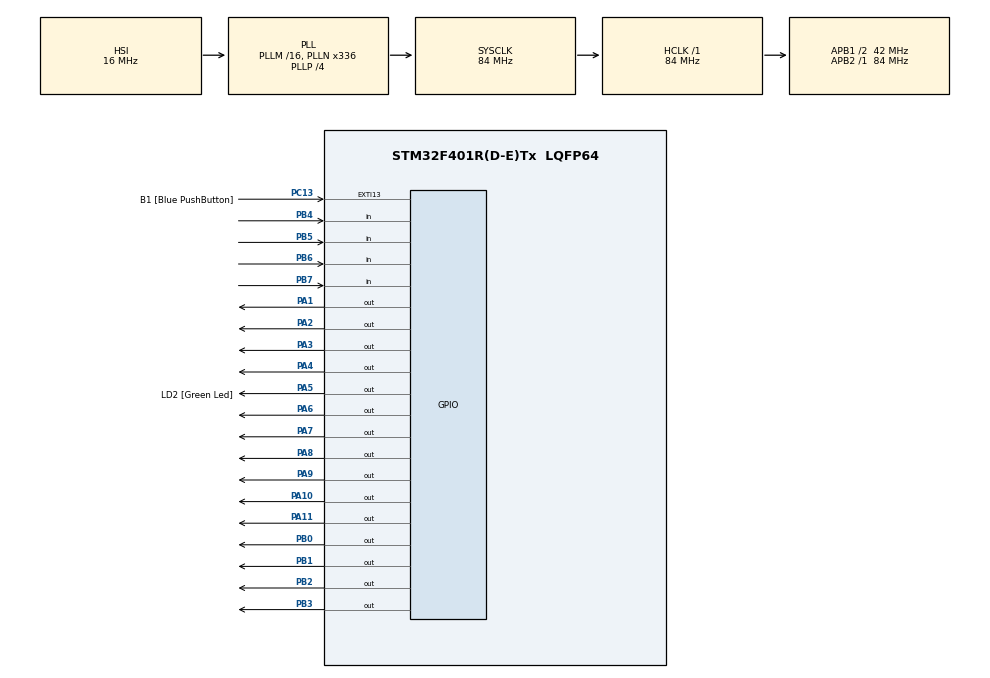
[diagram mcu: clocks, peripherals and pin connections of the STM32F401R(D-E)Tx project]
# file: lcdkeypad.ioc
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Mcu.Family=STM32F4
Mcu.Name=STM32F401R(D-E)Tx
Mcu.Package=LQFP64
NVIC.PriorityGroup=NVIC_PRIORITYGROUP_4
PA1.Signal=GPIO_Output
PA10.Signal=GPIO_Output
PA11.Signal=GPIO_Output
PA13.GPIO_Label=TMS
PA13.Signal=SYS_JTMS-SWDIO
PA14.GPIO_Label=TCK
PA14.Signal=SYS_JTCK-SWCLK
PA2.Signal=GPIO_Output
PA3.Signal=GPIO_Output
PA4.Signal=GPIO_Output
PA5.GPIO_Label=LD2 [Green Led]
PA5.GPIO_Mode=GPIO_MODE_OUTPUT_PP
PA5.GPIO_PuPd=GPIO_NOPULL
PA5.GPIO_Speed=GPIO_SPEED_FREQ_LOW
PA5.Signal=GPIO_Output
PA6.Signal=GPIO_Output
PA7.Signal=GPIO_Output
PA8.Signal=GPIO_Output
PA9.Signal=GPIO_Output
PB0.Signal=GPIO_Output
PB1.Signal=GPIO_Output
PB2.Signal=GPIO_Output
PB3.Signal=GPIO_Output
PB4.Signal=GPIO_Input
PB5.Signal=GPIO_Input
PB6.Signal=GPIO_Input
PB7.Signal=GPIO_Input
PC13-ANTI_TAMP.GPIO_Label=B1 [Blue PushButton]
PC13-ANTI_TAMP.GPIO_ModeDefaultEXTI=GPIO_MODE_IT_FALLING
PC13-ANTI_TAMP.GPIO_PuPd=GPIO_NOPULL
PC13-ANTI_TAMP.Signal=GPXTI13
PC14-OSC32_IN.Mode=LSE-External-Oscillator
PC14-OSC32_IN.Signal=RCC_OSC32_IN
PC15-OSC32_OUT.Mode=LSE-External-Oscillator
PC15-OSC32_OUT.Signal=RCC_OSC32_OUT
PH0\ -\ OSC_IN.Mode=HSE-External-Clock-Source
PH0\ -\ OSC_IN.Signal=RCC_OSC_IN
PH1\ -\ OSC_OUT.Mode=HSE-External-Clock-Source
PH1\ -\ OSC_OUT.Signal=RCC_OSC_OUT
ProjectManager.HeapSize=0x200
ProjectManager.StackSize=0x400
ProjectManager.TargetToolchain=STM32CubeIDE
RCC.48MHZClocksFreq_Value=48000000
RCC.AHBFreq_Value=84000000
RCC.APB1CLKDivider=RCC_HCLK_DIV2
RCC.APB1Freq_Value=42000000
RCC.APB1TimFreq_Value=84000000
RCC.APB2Freq_Value=84000000
RCC.APB2TimFreq_Value=84000000
RCC.CortexFreq_Value=84000000
RCC.HCLKFreq_Value=84000000
RCC.HSE_VALUE=8000000
RCC.HSI_VALUE=16000000
RCC.PLLN=336
RCC.PLLP=RCC_PLLP_DIV4
RCC.PLLQ=7
RCC.SYSCLKFreq_VALUE=84000000
RCC.SYSCLKSource=RCC_SYSCLKSOURCE_PLLCLK
RCC.VCOOutputFreq_Value=336000000
board=NUCLEO-F401RE

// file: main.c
/* USER CODE BEGIN Header */
/**
  ******************************************************************************
  * @file           : main.c
  * @brief          : Main program body
  ******************************************************************************
  * @attention
  *
  * Copyright (c) 2025 STMicroelectronics.
  * All rights reserved.
  *
  * This software is licensed under terms that can be found in the LICENSE file
  * in the root directory of this software component.
  * If no LICENSE file comes with this software, it is provided AS-IS.
  *
  ******************************************************************************
  */
/* USER CODE END Header */
#include "main.h"

void SystemClock_Config(void);
static void MX_GPIO_Init(void);
/* USER CODE BEGIN PFP */

data_pin[0] = GPIO_PIN_11;
data_pin[1] = GPIO_PIN_10;
data_pin[2] = GPIO_PIN_9;
data_pin[3] = GPIO_PIN_8;
data_pin[4] = GPIO_PIN_7;
data_pin[5] = GPIO_PIN_6;
data_pin[6] = GPIO_PIN_5;
data_pin[7] = GPIO_PIN_4;
/* USER CODE END PFP */

int main(void)
{

  /* MCU Configuration--------------------------------------------------------*/

  /* Reset of all peripherals, Initializes the Flash interface and the Systick. */
  HAL_Init();

  /* Configure the system clock */
  SystemClock_Config();

  /* Initialize all configured peripherals */
  MX_GPIO_Init();
  lcd_init();
  HAL_Delay(10);
  lcd_str((uint8_t*) "Welcome to STM32");
  lcd_cmd(0x38);
  lcd_cmd(0xC0);
  /* Infinite loop */
  while (1) {
  key_detect();
  HAL_Delay(100);
  }
  }
  void key_detect(void) {
  HAL_GPIO_WritePin(GPIOB, GPIO_PIN_3, 0);
  HAL_GPIO_WritePin(GPIOB, GPIO_PIN_2, 1);
  HAL_GPIO_WritePin(GPIOB, GPIO_PIN_1, 1);
  HAL_GPIO_WritePin(GPIOB, GPIO_PIN_0, 1);
  if (HAL_GPIO_ReadPin(GPIOB, GPIO_PIN_7) == 0) {
  //1
  lcd_cmd(0x01);
  lcd_str((uint8_t*) "You Pressed: ");
  lcd_cmd(0x38);
  lcd_cmd(0xc0);
  lcd_str((uint8_t*) "1");
  //while (HAL_GPIO_ReadPin(GPIOB, GPIO_PIN_7));
  }
  if (HAL_GPIO_ReadPin(GPIOB, GPIO_PIN_6) == 0) {
  //2
  lcd_cmd(0x01);
  lcd_str((uint8_t*) "You Pressed: ");
  lcd_cmd(0x38);
  lcd_cmd(0xc0);
  lcd_str((uint8_t*) "2");
  //while (HAL_GPIO_ReadPin(GPIOB, GPIO_PIN_6));
  }
  if (HAL_GPIO_ReadPin(GPIOB, GPIO_PIN_5) == 0) {
  //2
  lcd_cmd(0x01);
  lcd_str((uint8_t*) "You Pressed: ");
  lcd_cmd(0x38);
  lcd_cmd(0xc0);
  lcd_str((uint8_t*) "3");
  //while (HAL_GPIO_ReadPin(GPIOB, GPIO_PIN_5));
  }
  if (HAL_GPIO_ReadPin(GPIOB, GPIO_PIN_4) == 0) {
  //2
  lcd_cmd(0x01);
  lcd_str((uint8_t*) "You Pressed: ");
  lcd_cmd(0x38);
  lcd_cmd(0xc0);
  lcd_str((uint8_t*) "A");
  //while (HAL_GPIO_ReadPin(GPIOB, GPIO_PIN_4));
  }
  HAL_GPIO_WritePin(GPIOB, GPIO_PIN_3, 1);
  HAL_GPIO_WritePin(GPIOB, GPIO_PIN_2, 0);
  HAL_GPIO_WritePin(GPIOB, GPIO_PIN_1, 1);
  HAL_GPIO_WritePin(GPIOB, GPIO_PIN_0, 1);
  if (HAL_GPIO_ReadPin(GPIOB, GPIO_PIN_7) == 0) {
  //1
  lcd_cmd(0x01);
  lcd_str((uint8_t*) "You Pressed: ");
  lcd_cmd(0x38);
  lcd_cmd(0xc0);
  lcd_str((uint8_t*) "4");
  //while (HAL_GPIO_ReadPin(GPIOB, GPIO_PIN_7));
  }
  if (HAL_GPIO_ReadPin(GPIOB, GPIO_PIN_6) == 0) {
  //2
  lcd_cmd(0x01);
  lcd_str((uint8_t*) "You Pressed: ");
  lcd_cmd(0x38);
  lcd_cmd(0xc0);
  lcd_str((uint8_t*) "5");
  //while (HAL_GPIO_ReadPin(GPIOB, GPIO_PIN_6));
  }
  if (HAL_GPIO_ReadPin(GPIOB, GPIO_PIN_5) == 0) {
  //2
  lcd_cmd(0x01);
  lcd_str((uint8_t*) "You Pressed: ");
  lcd_cmd(0x38);
  lcd_cmd(0xc0);
  lcd_str((uint8_t*) "6");
  //while (HAL_GPIO_ReadPin(GPIOB, GPIO_PIN_5));
  }
  if (HAL_GPIO_ReadPin(GPIOB, GPIO_PIN_4) == 0) {
  //2
  lcd_cmd(0x01);
  lcd_str((uint8_t*) "You Pressed: ");
  lcd_cmd(0x38);
  lcd_cmd(0xc0);
  lcd_str((uint8_t*) "B");
  //while (HAL_GPIO_ReadPin(GPIOB, GPIO_PIN_4));
  }
  HAL_GPIO_WritePin(GPIOB, GPIO_PIN_3, 1);
  HAL_GPIO_WritePin(GPIOB, GPIO_PIN_2, 1);
  HAL_GPIO_WritePin(GPIOB, GPIO_PIN_1, 0);
  HAL_GPIO_WritePin(GPIOB, GPIO_PIN_0, 1);
  if (HAL_GPIO_ReadPin(GPIOB, GPIO_PIN_7) == 0) {
  //1
  lcd_cmd(0x01);
  lcd_str((uint8_t*) "You Pressed: ");
  lcd_cmd(0x38);
  lcd_cmd(0xc0);
  lcd_str((uint8_t*) "7");
  //while (HAL_GPIO_ReadPin(GPIOB, GPIO_PIN_7));
  }
  if (HAL_GPIO_ReadPin(GPIOB, GPIO_PIN_6) == 0) {
  //2
  lcd_cmd(0x01);
  lcd_str((uint8_t*) "You Pressed: ");
  lcd_cmd(0x38);
  lcd_cmd(0xc0);
  lcd_str((uint8_t*) "8");
  //while (HAL_GPIO_ReadPin(GPIOB, GPIO_PIN_6));
  }
  if (HAL_GPIO_ReadPin(GPIOB, GPIO_PIN_5) == 0) {
  //2
  lcd_cmd(0x01);
  lcd_str((uint8_t*) "You Pressed: ");
  lcd_cmd(0x38);
  lcd_cmd(0xc0);
  lcd_str((uint8_t*) "9");
  //while (HAL_GPIO_ReadPin(GPIOB, GPIO_PIN_5));
  }
  if (HAL_GPIO_ReadPin(GPIOB, GPIO_PIN_4) == 0) {
  //2
  lcd_cmd(0x01);
  lcd_str((uint8_t*) "You Pressed: ");
  lcd_cmd(0x38);
  lcd_cmd(0xc0);
  lcd_str((uint8_t*) "C");
  //while (HAL_GPIO_ReadPin(GPIOB, GPIO_PIN_4));
  }
  HAL_GPIO_WritePin(GPIOB, GPIO_PIN_3, 0);
  HAL_GPIO_WritePin(GPIOB, GPIO_PIN_2, 0);
  HAL_GPIO_WritePin(GPIOB, GPIO_PIN_1, 0);
  HAL_GPIO_WritePin(GPIOB, GPIO_PIN_0, 1);
  if (HAL_GPIO_ReadPin(GPIOB, GPIO_PIN_7) == 0) {
  //1
  lcd_cmd(0x01);
  lcd_str((uint8_t*) "You Pressed: ");
  lcd_cmd(0x38);
  lcd_cmd(0xc0);
  lcd_str((uint8_t*) "*");
  //while (HAL_GPIO_ReadPin(GPIOB, GPIO_PIN_7));
  }
  if (HAL_GPIO_ReadPin(GPIOB, GPIO_PIN_6) == 0) {
  //2
  lcd_cmd(0x01);
  lcd_str((uint8_t*) "You Pressed: ");
  lcd_cmd(0x38);
  lcd_cmd(0xc0);
  lcd_str((uint8_t*) "0");
  //while (HAL_GPIO_ReadPin(GPIOB, GPIO_PIN_6));
  }
  if (HAL_GPIO_ReadPin(GPIOB, GPIO_PIN_5) == 0) {
  //2
  lcd_cmd(0x01);
  lcd_str((uint8_t*) "You Pressed: ");
  lcd_cmd(0x38);
  lcd_cmd(0xc0);
  lcd_str((uint8_t*) "#");
  //while (HAL_GPIO_ReadPin(GPIOB, GPIO_PIN_5));
  }
  if (HAL_GPIO_ReadPin(GPIOB, GPIO_PIN_4) == 0) {
  //2
  lcd_cmd(0x01);
  lcd_str((uint8_t*) "You Pressed: ");
  lcd_cmd(0x38);
  lcd_cmd(0xc0);
  lcd_str((uint8_t*) "D");
  //while (HAL_GPIO_ReadPin(GPIOB, GPIO_PIN_4));
  }
  }
  void lcd_init(void) {
  HAL_Delay(100);
  lcd_cmd(0x38);
  lcd_cmd(0x38);
  lcd_cmd(0x38); // seting lcd to 8 bit mode
  lcd_cmd(0x0C); // Display On
  lcd_cmd(0x06); // Autoincement Display
  lcd_cmd(0x01); // clear lcd
  lcd_cmd(0x80);
  }
  void lcd_cmd(uint8_t value) {
  HAL_GPIO_WritePin(GPIOA, GPIO_PIN_1, 0);
  HAL_GPIO_WritePin(GPIOA, GPIO_PIN_2, 0);
  for (int i = 0; i < 8; i++) {
  HAL_GPIO_WritePin(GPIOA, data_pin[i],
  ((value >> i) & 0x01) ? GPIO_PIN_SET : GPIO_PIN_RESET);
  }
  HAL_GPIO_WritePin(GPIOA, GPIO_PIN_3, 1);
  HAL_Delay(1);
  HAL_GPIO_WritePin(GPIOA, GPIO_PIN_3, 0);
  HAL_Delay(1);
  }
  void lcd_data(uint8_t value) {
  HAL_GPIO_WritePin(GPIOA, GPIO_PIN_1, 1);
  HAL_GPIO_WritePin(GPIOA, GPIO_PIN_2, 0);
  for (int i = 0; i < 8; i++) {
  HAL_GPIO_WritePin(GPIOA, data_pin[i],
  ((value >> i) & 0x01) ? GPIO_PIN_SET : GPIO_PIN_RESET);
  }
  HAL_GPIO_WritePin(GPIOA, GPIO_PIN_3, 1);
  HAL_Delay(1);
  HAL_GPIO_WritePin(GPIOA, GPIO_PIN_3, 0);
  HAL_Delay(1);
  }
  void lcd_str(uint8_t *str) {
  int j = 0;
  while (str[j] != '\0') {
  lcd_data(str[j]);
  j++;
  }
  }

void SystemClock_Config(void)
{
  RCC_OscInitTypeDef RCC_OscInitStruct = {0};
  RCC_ClkInitTypeDef RCC_ClkInitStruct = {0};

  /** Configure the main internal regulator output voltage
  */
  __HAL_RCC_PWR_CLK_ENABLE();
  __HAL_PWR_VOLTAGESCALING_CONFIG(PWR_REGULATOR_VOLTAGE_SCALE2);

  /** Initializes the RCC Oscillators according to the specified parameters
  * in the RCC_OscInitTypeDef structure.
  */
  RCC_OscInitStruct.OscillatorType = RCC_OSCILLATORTYPE_HSI;
  RCC_OscInitStruct.HSIState = RCC_HSI_ON;
  RCC_OscInitStruct.HSICalibrationValue = RCC_HSICALIBRATION_DEFAULT;
  RCC_OscInitStruct.PLL.PLLState = RCC_PLL_ON;
  RCC_OscInitStruct.PLL.PLLSource = RCC_PLLSOURCE_HSI;
  RCC_OscInitStruct.PLL.PLLM = 16;
  RCC_OscInitStruct.PLL.PLLN = 336;
  RCC_OscInitStruct.PLL.PLLP = RCC_PLLP_DIV4;
  RCC_OscInitStruct.PLL.PLLQ = 7;
  if (HAL_RCC_OscConfig(&RCC_OscInitStruct) != HAL_OK)
  {
    Error_Handler();
  }

  /** Initializes the CPU, AHB and APB buses clocks
  */
  RCC_ClkInitStruct.ClockType = RCC_CLOCKTYPE_HCLK|RCC_CLOCKTYPE_SYSCLK
                              |RCC_CLOCKTYPE_PCLK1|RCC_CLOCKTYPE_PCLK2;
  RCC_ClkInitStruct.SYSCLKSource = RCC_SYSCLKSOURCE_PLLCLK;
  RCC_ClkInitStruct.AHBCLKDivider = RCC_SYSCLK_DIV1;
  RCC_ClkInitStruct.APB1CLKDivider = RCC_HCLK_DIV2;
  RCC_ClkInitStruct.APB2CLKDivider = RCC_HCLK_DIV1;

  if (HAL_RCC_ClockConfig(&RCC_ClkInitStruct, FLASH_LATENCY_2) != HAL_OK)
  {
    Error_Handler();
  }
}

static void MX_GPIO_Init(void)
{
  GPIO_InitTypeDef GPIO_InitStruct = {0};

  /* GPIO Ports Clock Enable */
  __HAL_RCC_GPIOC_CLK_ENABLE();
  __HAL_RCC_GPIOH_CLK_ENABLE();
  __HAL_RCC_GPIOA_CLK_ENABLE();
  __HAL_RCC_GPIOB_CLK_ENABLE();

  /*Configure GPIO pin Output Level */
  HAL_GPIO_WritePin(GPIOA, GPIO_PIN_1|GPIO_PIN_2|GPIO_PIN_3|GPIO_PIN_4
                          |LD2_Pin|GPIO_PIN_6|GPIO_PIN_7|GPIO_PIN_8
                          |GPIO_PIN_9|GPIO_PIN_10|GPIO_PIN_11, GPIO_PIN_RESET);

  /*Configure GPIO pin Output Level */
  HAL_GPIO_WritePin(GPIOB, GPIO_PIN_0|GPIO_PIN_1|GPIO_PIN_2|GPIO_PIN_3, GPIO_PIN_RESET);

  /*Configure GPIO pin : B1_Pin */
  GPIO_InitStruct.Pin = B1_Pin;
  GPIO_InitStruct.Mode = GPIO_MODE_IT_FALLING;
  GPIO_InitStruct.Pull = GPIO_NOPULL;
  HAL_GPIO_Init(B1_GPIO_Port, &GPIO_InitStruct);

  /*Configure GPIO pins : PA1 PA2 PA3 PA4
                           LD2_Pin PA6 PA7 PA8
                           PA9 PA10 PA11 */
  GPIO_InitStruct.Pin = GPIO_PIN_1|GPIO_PIN_2|GPIO_PIN_3|GPIO_PIN_4
                          |LD2_Pin|GPIO_PIN_6|GPIO_PIN_7|GPIO_PIN_8
                          |GPIO_PIN_9|GPIO_PIN_10|GPIO_PIN_11;
  GPIO_InitStruct.Mode = GPIO_MODE_OUTPUT_PP;
  GPIO_InitStruct.Pull = GPIO_NOPULL;
  GPIO_InitStruct.Speed = GPIO_SPEED_FREQ_LOW;
  HAL_GPIO_Init(GPIOA, &GPIO_InitStruct);

  /*Configure GPIO pins : PB0 PB1 PB2 PB3 */
  GPIO_InitStruct.Pin = GPIO_PIN_0|GPIO_PIN_1|GPIO_PIN_2|GPIO_PIN_3;
  GPIO_InitStruct.Mode = GPIO_MODE_OUTPUT_PP;
  GPIO_InitStruct.Pull = GPIO_NOPULL;
  GPIO_InitStruct.Speed = GPIO_SPEED_FREQ_LOW;
  HAL_GPIO_Init(GPIOB, &GPIO_InitStruct);

  /*Configure GPIO pins : PB4 PB5 PB6 PB7 */
  GPIO_InitStruct.Pin = GPIO_PIN_4|GPIO_PIN_5|GPIO_PIN_6|GPIO_PIN_7;
  GPIO_InitStruct.Mode = GPIO_MODE_INPUT;
  GPIO_InitStruct.Pull = GPIO_NOPULL;
  HAL_GPIO_Init(GPIOB, &GPIO_InitStruct);

}

void Error_Handler(void)
{
  __disable_irq();
  while (1)
  {
  }
}
